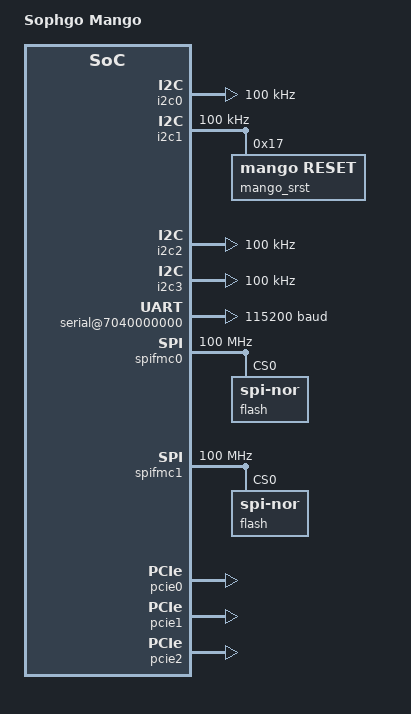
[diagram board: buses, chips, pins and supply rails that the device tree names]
/dts-v1/;

/ {
	model = "Sophgo Mango";
	compatible = "sophgo,mango";
	#address-cells = <2>;
	#size-cells = <2>;
	dma-noncoherent;

	info {
		file-name = "mango-sophgo-x4evb.dts";
	};

	cpus {
		#address-cells = <1>;
		#size-cells = <0>;
		timebase-frequency = <50000000>;

		cpu0: cpu@0 {
			compatible = "thead,c920", "riscv";
			device_type = "cpu";
			riscv,isa = "rv64imafdc_xtheadvector";
			riscv,isa-base = "rv64i";
			riscv,isa-extensions = "i", "m", "a", "f", "d", "c",
					"zicntr", "zicsr", "zifencei",
					"zihpm", "xtheadvector";
			reg = <0>;
			i-cache-block-size = <64>;
			i-cache-size = <65536>;
			i-cache-sets = <512>;
			d-cache-block-size = <64>;
			d-cache-size = <65536>;
			d-cache-sets = <512>;
			next-level-cache = <&l2_cache0>;
			mmu-type = "riscv,sv39";
			numa-node-id = <0>;

			cpu0_intc: interrupt-controller {
				#address-cells = <1>;
				compatible = "riscv,cpu-intc";
				interrupt-controller;
				#interrupt-cells = <1>;
			};
		};

		cpu1: cpu@1 {
			compatible = "thead,c920", "riscv";
			device_type = "cpu";
			riscv,isa = "rv64imafdc_xtheadvector";
			riscv,isa-base = "rv64i";
			riscv,isa-extensions = "i", "m", "a", "f", "d", "c",
					"zicntr", "zicsr", "zifencei",
					"zihpm", "xtheadvector";
			reg = <1>;
			i-cache-block-size = <64>;
			i-cache-size = <65536>;
			i-cache-sets = <512>;
			d-cache-block-size = <64>;
			d-cache-size = <65536>;
			d-cache-sets = <512>;
			next-level-cache = <&l2_cache0>;
			mmu-type = "riscv,sv39";
			numa-node-id = <0>;

			cpu1_intc: interrupt-controller {
				#address-cells = <1>;
				compatible = "riscv,cpu-intc";
				interrupt-controller;
				#interrupt-cells = <1>;
			};
		};

		cpu2: cpu@2 {
			compatible = "thead,c920", "riscv";
			device_type = "cpu";
			riscv,isa = "rv64imafdc_xtheadvector";
			riscv,isa-base = "rv64i";
			riscv,isa-extensions = "i", "m", "a", "f", "d", "c",
					"zicntr", "zicsr", "zifencei",
					"zihpm", "xtheadvector";
			reg = <2>;
			i-cache-size = <65536>;
			i-cache-sets = <512>;
			d-cache-block-size = <64>;
			d-cache-size = <65536>;
			d-cache-sets = <512>;
			next-level-cache = <&l2_cache0>;
			mmu-type = "riscv,sv39";
			numa-node-id = <0>;

			cpu2_intc: interrupt-controller {
				#address-cells = <1>;
				compatible = "riscv,cpu-intc";
				interrupt-controller;
				#interrupt-cells = <1>;
			};
		};

		cpu3: cpu@3 {
			compatible = "thead,c920", "riscv";
			device_type = "cpu";
			riscv,isa = "rv64imafdc_xtheadvector";
			riscv,isa-base = "rv64i";
			riscv,isa-extensions = "i", "m", "a", "f", "d", "c",
					"zicntr", "zicsr", "zifencei",
					"zihpm", "xtheadvector";
			reg = <3>;
			i-cache-size = <65536>;
			i-cache-sets = <512>;
			d-cache-block-size = <64>;
			d-cache-size = <65536>;
			d-cache-sets = <512>;
			next-level-cache = <&l2_cache0>;
			mmu-type = "riscv,sv39";
			numa-node-id = <0>;

			cpu3_intc: interrupt-controller {
				#address-cells = <1>;
				compatible = "riscv,cpu-intc";
				interrupt-controller;
				#interrupt-cells = <1>;
			};
		};

		cpu4: cpu@4 {
			compatible = "thead,c920", "riscv";
			device_type = "cpu";
			riscv,isa = "rv64imafdc_xtheadvector";
			riscv,isa-base = "rv64i";
			riscv,isa-extensions = "i", "m", "a", "f", "d", "c",
					"zicntr", "zicsr", "zifencei",
					"zihpm", "xtheadvector";
			reg = <4>;
			i-cache-size = <65536>;
			i-cache-sets = <512>;
			d-cache-block-size = <64>;
			d-cache-size = <65536>;
			d-cache-sets = <512>;
			next-level-cache = <&l2_cache1>;
			mmu-type = "riscv,sv39";
			numa-node-id = <0>;

			cpu4_intc: interrupt-controller {
				#address-cells = <1>;
				compatible = "riscv,cpu-intc";
				interrupt-controller;
				#interrupt-cells = <1>;
			};
		};

		cpu5: cpu@5 {
			compatible = "thead,c920", "riscv";
			device_type = "cpu";
			riscv,isa = "rv64imafdc_xtheadvector";
			riscv,isa-base = "rv64i";
			riscv,isa-extensions = "i", "m", "a", "f", "d", "c",
					"zicntr", "zicsr", "zifencei",
					"zihpm", "xtheadvector";
			reg = <5>;
			i-cache-size = <65536>;
			i-cache-sets = <512>;
			d-cache-block-size = <64>;
			d-cache-size = <65536>;
			d-cache-sets = <512>;
			next-level-cache = <&l2_cache1>;
			mmu-type = "riscv,sv39";
			numa-node-id = <0>;

			cpu5_intc: interrupt-controller {
				#address-cells = <1>;
				compatible = "riscv,cpu-intc";
				interrupt-controller;
				#interrupt-cells = <1>;
			};
		};

		cpu6: cpu@6 {
			compatible = "thead,c920", "riscv";
			device_type = "cpu";
			riscv,isa = "rv64imafdc_xtheadvector";
			riscv,isa-base = "rv64i";
			riscv,isa-extensions = "i", "m", "a", "f", "d", "c",
					"zicntr", "zicsr", "zifencei",
					"zihpm", "xtheadvector";
			reg = <6>;
			i-cache-size = <65536>;
			i-cache-sets = <512>;
			d-cache-block-size = <64>;
			d-cache-size = <65536>;
			d-cache-sets = <512>;
			next-level-cache = <&l2_cache1>;
			mmu-type = "riscv,sv39";
			numa-node-id = <0>;

			cpu6_intc: interrupt-controller {
				#address-cells = <1>;
				compatible = "riscv,cpu-intc";
				interrupt-controller;
				#interrupt-cells = <1>;
			};
		};

		cpu7: cpu@7 {
			compatible = "thead,c920", "riscv";
			device_type = "cpu";
			riscv,isa = "rv64imafdc_xtheadvector";
			riscv,isa-base = "rv64i";
			riscv,isa-extensions = "i", "m", "a", "f", "d", "c",
					"zicntr", "zicsr", "zifencei",
					"zihpm", "xtheadvector";
			reg = <7>;
			i-cache-size = <65536>;
			i-cache-sets = <512>;
			d-cache-block-size = <64>;
			d-cache-size = <65536>;
			d-cache-sets = <512>;
			next-level-cache = <&l2_cache1>;
			mmu-type = "riscv,sv39";
			numa-node-id = <0>;

			cpu7_intc: interrupt-controller {
				#address-cells = <1>;
				compatible = "riscv,cpu-intc";
				interrupt-controller;
				#interrupt-cells = <1>;
			};
		};

		cpu8: cpu@8 {
			compatible = "thead,c920", "riscv";
			device_type = "cpu";
			riscv,isa = "rv64imafdc_xtheadvector";
			riscv,isa-base = "rv64i";
			riscv,isa-extensions = "i", "m", "a", "f", "d", "c",
					"zicntr", "zicsr", "zifencei",
					"zihpm", "xtheadvector";
			reg = <8>;
			i-cache-size = <65536>;
			i-cache-sets = <512>;
			d-cache-block-size = <64>;
			d-cache-size = <65536>;
			d-cache-sets = <512>;
			next-level-cache = <&l2_cache4>;
			mmu-type = "riscv,sv39";
			numa-node-id = <1>;

			cpu8_intc: interrupt-controller {
				#address-cells = <1>;
				compatible = "riscv,cpu-intc";
				interrupt-controller;
				#interrupt-cells = <1>;
			};
		};

		cpu9: cpu@9 {
			compatible = "thead,c920", "riscv";
			device_type = "cpu";
			riscv,isa = "rv64imafdc_xtheadvector";
			riscv,isa-base = "rv64i";
			riscv,isa-extensions = "i", "m", "a", "f", "d", "c",
					"zicntr", "zicsr", "zifencei",
					"zihpm", "xtheadvector";
			reg = <9>;
			i-cache-size = <65536>;
			i-cache-sets = <512>;
			d-cache-block-size = <64>;
			d-cache-size = <65536>;
			d-cache-sets = <512>;
			next-level-cache = <&l2_cache4>;
			mmu-type = "riscv,sv39";
			numa-node-id = <1>;

			cpu9_intc: interrupt-controller {
				#address-cells = <1>;
				compatible = "riscv,cpu-intc";
				interrupt-controller;
				#interrupt-cells = <1>;
			};
		};

		cpu10: cpu@10 {
			compatible = "thead,c920", "riscv";
			device_type = "cpu";
			riscv,isa = "rv64imafdc_xtheadvector";
			riscv,isa-base = "rv64i";
			riscv,isa-extensions = "i", "m", "a", "f", "d", "c",
					"zicntr", "zicsr", "zifencei",
					"zihpm", "xtheadvector";
			reg = <10>;
			i-cache-size = <65536>;
			i-cache-sets = <512>;
			d-cache-block-size = <64>;
			d-cache-size = <65536>;
			d-cache-sets = <512>;
			next-level-cache = <&l2_cache4>;
			mmu-type = "riscv,sv39";
			numa-node-id = <1>;

			cpu10_intc: interrupt-controller {
				#address-cells = <1>;
				compatible = "riscv,cpu-intc";
				interrupt-controller;
				#interrupt-cells = <1>;
			};
		};

		cpu11: cpu@11 {
			compatible = "thead,c920", "riscv";
			device_type = "cpu";
			riscv,isa = "rv64imafdc_xtheadvector";
			riscv,isa-base = "rv64i";
			riscv,isa-extensions = "i", "m", "a", "f", "d", "c",
					"zicntr", "zicsr", "zifencei",
					"zihpm", "xtheadvector";
			reg = <11>;
			i-cache-size = <65536>;
			i-cache-sets = <512>;
			d-cache-block-size = <64>;
			d-cache-size = <65536>;
			d-cache-sets = <512>;
			next-level-cache = <&l2_cache4>;
			mmu-type = "riscv,sv39";
			numa-node-id = <1>;

			cpu11_intc: interrupt-controller {
				#address-cells = <1>;
				compatible = "riscv,cpu-intc";
				interrupt-controller;
				#interrupt-cells = <1>;
			};
		};

		cpu12: cpu@12 {
			compatible = "thead,c920", "riscv";
			device_type = "cpu";
			riscv,isa = "rv64imafdc_xtheadvector";
			riscv,isa-base = "rv64i";
			riscv,isa-extensions = "i", "m", "a", "f", "d", "c",
					"zicntr", "zicsr", "zifencei",
					"zihpm", "xtheadvector";
			reg = <12>;
			i-cache-size = <65536>;
			i-cache-sets = <512>;
			d-cache-block-size = <64>;
			d-cache-size = <65536>;
			d-cache-sets = <512>;
			next-level-cache = <&l2_cache5>;
			mmu-type = "riscv,sv39";
			numa-node-id = <1>;

			cpu12_intc: interrupt-controller {
				#address-cells = <1>;
				compatible = "riscv,cpu-intc";
				interrupt-controller;
				#interrupt-cells = <1>;
			};
		};

		cpu13: cpu@13 {
			compatible = "thead,c920", "riscv";
			device_type = "cpu";
			riscv,isa = "rv64imafdc_xtheadvector";
			riscv,isa-base = "rv64i";
			riscv,isa-extensions = "i", "m", "a", "f", "d", "c",
					"zicntr", "zicsr", "zifencei",
					"zihpm", "xtheadvector";
			reg = <13>;
			i-cache-size = <65536>;
			i-cache-sets = <512>;
			d-cache-block-size = <64>;
			d-cache-size = <65536>;
			d-cache-sets = <512>;
			next-level-cache = <&l2_cache5>;
			mmu-type = "riscv,sv39";
			numa-node-id = <1>;

			cpu13_intc: interrupt-controller {
				#address-cells = <1>;
				compatible = "riscv,cpu-intc";
				interrupt-controller;
				#interrupt-cells = <1>;
			};
		};

		cpu14: cpu@14 {
			compatible = "thead,c920", "riscv";
			device_type = "cpu";
			riscv,isa = "rv64imafdc_xtheadvector";
			riscv,isa-base = "rv64i";
			riscv,isa-extensions = "i", "m", "a", "f", "d", "c",
					"zicntr", "zicsr", "zifencei",
					"zihpm", "xtheadvector";
			reg = <14>;
			i-cache-size = <65536>;
			i-cache-sets = <512>;
			d-cache-block-size = <64>;
			d-cache-size = <65536>;
			d-cache-sets = <512>;
			next-level-cache = <&l2_cache5>;
			mmu-type = "riscv,sv39";
			numa-node-id = <1>;

			cpu14_intc: interrupt-controller {
				#address-cells = <1>;
				compatible = "riscv,cpu-intc";
				interrupt-controller;
				#interrupt-cells = <1>;
			};
		};

		cpu15: cpu@15 {
			compatible = "thead,c920", "riscv";
			device_type = "cpu";
			riscv,isa = "rv64imafdc_xtheadvector";
			riscv,isa-base = "rv64i";
			riscv,isa-extensions = "i", "m", "a", "f", "d", "c",
					"zicntr", "zicsr", "zifencei",
					"zihpm", "xtheadvector";
			reg = <15>;
			i-cache-size = <65536>;
			i-cache-sets = <512>;
			d-cache-block-size = <64>;
			d-cache-size = <65536>;
			d-cache-sets = <512>;
			next-level-cache = <&l2_cache5>;
			mmu-type = "riscv,sv39";
			numa-node-id = <1>;

			cpu15_intc: interrupt-controller {
				#address-cells = <1>;
				compatible = "riscv,cpu-intc";
				interrupt-controller;
				#interrupt-cells = <1>;
			};
		};

		cpu16: cpu@16 {
			compatible = "thead,c920", "riscv";
			device_type = "cpu";
			riscv,isa = "rv64imafdc_xtheadvector";
			riscv,isa-base = "rv64i";
			riscv,isa-extensions = "i", "m", "a", "f", "d", "c",
					"zicntr", "zicsr", "zifencei",
					"zihpm", "xtheadvector";
			reg = <16>;
			i-cache-size = <65536>;
			i-cache-sets = <512>;
			d-cache-block-size = <64>;
			d-cache-size = <65536>;
			d-cache-sets = <512>;
			next-level-cache = <&l2_cache2>;
			mmu-type = "riscv,sv39";
			numa-node-id = <0>;

			cpu16_intc: interrupt-controller {
				#address-cells = <1>;
				compatible = "riscv,cpu-intc";
				interrupt-controller;
				#interrupt-cells = <1>;
			};
		};

		cpu17: cpu@17 {
			compatible = "thead,c920", "riscv";
			device_type = "cpu";
			riscv,isa = "rv64imafdc_xtheadvector";
			riscv,isa-base = "rv64i";
			riscv,isa-extensions = "i", "m", "a", "f", "d", "c",
					"zicntr", "zicsr", "zifencei",
					"zihpm", "xtheadvector";
			reg = <17>;
			i-cache-size = <65536>;
			i-cache-sets = <512>;
			d-cache-block-size = <64>;
			d-cache-size = <65536>;
			d-cache-sets = <512>;
			next-level-cache = <&l2_cache2>;
			mmu-type = "riscv,sv39";
			numa-node-id = <0>;

			cpu17_intc: interrupt-controller {
				#address-cells = <1>;
				compatible = "riscv,cpu-intc";
				interrupt-controller;
				#interrupt-cells = <1>;
			};
		};

		cpu18: cpu@18 {
			compatible = "thead,c920", "riscv";
			device_type = "cpu";
			riscv,isa = "rv64imafdc_xtheadvector";
			riscv,isa-base = "rv64i";
			riscv,isa-extensions = "i", "m", "a", "f", "d", "c",
					"zicntr", "zicsr", "zifencei",
					"zihpm", "xtheadvector";
			reg = <18>;
			i-cache-size = <65536>;
			i-cache-sets = <512>;
			d-cache-block-size = <64>;
			d-cache-size = <65536>;
			d-cache-sets = <512>;
			next-level-cache = <&l2_cache2>;
			mmu-type = "riscv,sv39";
			numa-node-id = <0>;

			cpu18_intc: interrupt-controller {
				#address-cells = <1>;
				compatible = "riscv,cpu-intc";
				interrupt-controller;
				#interrupt-cells = <1>;
			};
		};

		cpu19: cpu@19 {
			compatible = "thead,c920", "riscv";
			device_type = "cpu";
			riscv,isa = "rv64imafdc_xtheadvector";
			riscv,isa-base = "rv64i";
			riscv,isa-extensions = "i", "m", "a", "f", "d", "c",
					"zicntr", "zicsr", "zifencei",
					"zihpm", "xtheadvector";
			reg = <19>;
			i-cache-size = <65536>;
			i-cache-sets = <512>;
			d-cache-block-size = <64>;
			d-cache-size = <65536>;
			d-cache-sets = <512>;
			next-level-cache = <&l2_cache2>;
			mmu-type = "riscv,sv39";
			numa-node-id = <0>;

			cpu19_intc: interrupt-controller {
				#address-cells = <1>;
				compatible = "riscv,cpu-intc";
				interrupt-controller;
				#interrupt-cells = <1>;
			};
		};

		cpu20: cpu@20 {
			compatible = "thead,c920", "riscv";
			device_type = "cpu";
			riscv,isa = "rv64imafdc_xtheadvector";
			riscv,isa-base = "rv64i";
			riscv,isa-extensions = "i", "m", "a", "f", "d", "c",
					"zicntr", "zicsr", "zifencei",
					"zihpm", "xtheadvector";
			reg = <20>;
			i-cache-size = <65536>;
			i-cache-sets = <512>;
			d-cache-block-size = <64>;
			d-cache-size = <65536>;
			d-cache-sets = <512>;
			next-level-cache = <&l2_cache3>;
			mmu-type = "riscv,sv39";
			numa-node-id = <0>;

			cpu20_intc: interrupt-controller {
				#address-cells = <1>;
				compatible = "riscv,cpu-intc";
				interrupt-controller;
				#interrupt-cells = <1>;
			};
		};

		cpu21: cpu@21 {
			compatible = "thead,c920", "riscv";
			device_type = "cpu";
			riscv,isa = "rv64imafdc_xtheadvector";
			riscv,isa-base = "rv64i";
			riscv,isa-extensions = "i", "m", "a", "f", "d", "c",
					"zicntr", "zicsr", "zifencei",
					"zihpm", "xtheadvector";
			reg = <21>;
			i-cache-size = <65536>;
			i-cache-sets = <512>;
			d-cache-block-size = <64>;
			d-cache-size = <65536>;
			d-cache-sets = <512>;
			next-level-cache = <&l2_cache3>;
			mmu-type = "riscv,sv39";
			numa-node-id = <0>;

			cpu21_intc: interrupt-controller {
				#address-cells = <1>;
				compatible = "riscv,cpu-intc";
				interrupt-controller;
				#interrupt-cells = <1>;
			};
		};

		cpu22: cpu@22 {
			compatible = "thead,c920", "riscv";
			device_type = "cpu";
			riscv,isa = "rv64imafdc_xtheadvector";
			riscv,isa-base = "rv64i";
			riscv,isa-extensions = "i", "m", "a", "f", "d", "c",
					"zicntr", "zicsr", "zifencei",
					"zihpm", "xtheadvector";
			reg = <22>;
			i-cache-size = <65536>;
			i-cache-sets = <512>;
			d-cache-block-size = <64>;
			d-cache-size = <65536>;
			d-cache-sets = <512>;
			next-level-cache = <&l2_cache3>;
			mmu-type = "riscv,sv39";
			numa-node-id = <0>;

			cpu22_intc: interrupt-controller {
				#address-cells = <1>;
				compatible = "riscv,cpu-intc";
				interrupt-controller;
				#interrupt-cells = <1>;
			};
		};

		cpu23: cpu@23 {
			compatible = "thead,c920", "riscv";
			device_type = "cpu";
			riscv,isa = "rv64imafdc_xtheadvector";
			riscv,isa-base = "rv64i";
			riscv,isa-extensions = "i", "m", "a", "f", "d", "c",
					"zicntr", "zicsr", "zifencei",
					"zihpm", "xtheadvector";
			reg = <23>;
			i-cache-block-size = <64>;
			i-cache-size = <65536>;
			i-cache-sets = <512>;
			d-cache-block-size = <64>;
			d-cache-size = <65536>;
			d-cache-sets = <512>;
			next-level-cache = <&l2_cache3>;
			mmu-type = "riscv,sv39";
			numa-node-id = <0>;

			cpu23_intc: interrupt-controller {
				#address-cells = <1>;
				compatible = "riscv,cpu-intc";
				interrupt-controller;
				#interrupt-cells = <1>;
			};
		};

		cpu24: cpu@24 {
			compatible = "thead,c920", "riscv";
			device_type = "cpu";
			riscv,isa = "rv64imafdc_xtheadvector";
			riscv,isa-base = "rv64i";
			riscv,isa-extensions = "i", "m", "a", "f", "d", "c",
					"zicntr", "zicsr", "zifencei",
					"zihpm", "xtheadvector";
			reg = <24>;
			i-cache-size = <65536>;
			i-cache-sets = <512>;
			d-cache-block-size = <64>;
			d-cache-size = <65536>;
			d-cache-sets = <512>;
			next-level-cache = <&l2_cache6>;
			mmu-type = "riscv,sv39";
			numa-node-id = <1>;

			cpu24_intc: interrupt-controller {
				#address-cells = <1>;
				compatible = "riscv,cpu-intc";
				interrupt-controller;
				#interrupt-cells = <1>;
			};
		};

		cpu25: cpu@25 {
			compatible = "thead,c920", "riscv";
			device_type = "cpu";
			riscv,isa = "rv64imafdc_xtheadvector";
			riscv,isa-base = "rv64i";
			riscv,isa-extensions = "i", "m", "a", "f", "d", "c",
					"zicntr", "zicsr", "zifencei",
					"zihpm", "xtheadvector";
			reg = <25>;
			i-cache-size = <65536>;
			i-cache-sets = <512>;
			d-cache-block-size = <64>;
			d-cache-size = <65536>;
			d-cache-sets = <512>;
			next-level-cache = <&l2_cache6>;
			mmu-type = "riscv,sv39";
			numa-node-id = <1>;

			cpu25_intc: interrupt-controller {
				#address-cells = <1>;
				compatible = "riscv,cpu-intc";
				interrupt-controller;
				#interrupt-cells = <1>;
			};
		};

		cpu26: cpu@26 {
			compatible = "thead,c920", "riscv";
			device_type = "cpu";
			riscv,isa = "rv64imafdc_xtheadvector";
			riscv,isa-base = "rv64i";
			riscv,isa-extensions = "i", "m", "a", "f", "d", "c",
					"zicntr", "zicsr", "zifencei",
					"zihpm", "xtheadvector";
			reg = <26>;
			i-cache-size = <65536>;
			i-cache-sets = <512>;
			d-cache-block-size = <64>;
			d-cache-size = <65536>;
			d-cache-sets = <512>;
			next-level-cache = <&l2_cache6>;
			mmu-type = "riscv,sv39";
			numa-node-id = <1>;

			cpu26_intc: interrupt-controller {
				#address-cells = <1>;
				compatible = "riscv,cpu-intc";
				interrupt-controller;
				#interrupt-cells = <1>;
			};
		};

		cpu27: cpu@27 {
			compatible = "thead,c920", "riscv";
			device_type = "cpu";
			riscv,isa = "rv64imafdc_xtheadvector";
			riscv,isa-base = "rv64i";
			riscv,isa-extensions = "i", "m", "a", "f", "d", "c",
					"zicntr", "zicsr", "zifencei",
					"zihpm", "xtheadvector";
			reg = <27>;
			i-cache-size = <65536>;
			i-cache-sets = <512>;
			d-cache-block-size = <64>;
			d-cache-size = <65536>;
			d-cache-sets = <512>;
			next-level-cache = <&l2_cache6>;
			mmu-type = "riscv,sv39";
			numa-node-id = <1>;

			cpu27_intc: interrupt-controller {
				#address-cells = <1>;
				compatible = "riscv,cpu-intc";
				interrupt-controller;
				#interrupt-cells = <1>;
			};
		};

		cpu28: cpu@28 {
			compatible = "thead,c920", "riscv";
			device_type = "cpu";
			riscv,isa = "rv64imafdc_xtheadvector";
			riscv,isa-base = "rv64i";
			riscv,isa-extensions = "i", "m", "a", "f", "d", "c",
					"zicntr", "zicsr", "zifencei",
					"zihpm", "xtheadvector";
			reg = <28>;
			i-cache-size = <65536>;
			i-cache-sets = <512>;
			d-cache-block-size = <64>;
			d-cache-size = <65536>;
			d-cache-sets = <512>;
			next-level-cache = <&l2_cache7>;
			mmu-type = "riscv,sv39";
			numa-node-id = <1>;

			cpu28_intc: interrupt-controller {
				#address-cells = <1>;
				compatible = "riscv,cpu-intc";
				interrupt-controller;
				#interrupt-cells = <1>;
			};
		};

		cpu29: cpu@29 {
			compatible = "thead,c920", "riscv";
			device_type = "cpu";
			riscv,isa = "rv64imafdc_xtheadvector";
			riscv,isa-base = "rv64i";
			riscv,isa-extensions = "i", "m", "a", "f", "d", "c",
					"zicntr", "zicsr", "zifencei",
					"zihpm", "xtheadvector";
			reg = <29>;
			i-cache-size = <65536>;
			i-cache-sets = <512>;
			d-cache-block-size = <64>;
			d-cache-size = <65536>;
			d-cache-sets = <512>;
			next-level-cache = <&l2_cache7>;
			mmu-type = "riscv,sv39";
			numa-node-id = <1>;

			cpu29_intc: interrupt-controller {
				#address-cells = <1>;
				compatible = "riscv,cpu-intc";
				interrupt-controller;
				#interrupt-cells = <1>;
			};
		};

		cpu30: cpu@30 {
			compatible = "thead,c920", "riscv";
			device_type = "cpu";
			riscv,isa = "rv64imafdc_xtheadvector";
			riscv,isa-base = "rv64i";
			riscv,isa-extensions = "i", "m", "a", "f", "d", "c",
					"zicntr", "zicsr", "zifencei",
					"zihpm", "xtheadvector";
			reg = <30>;
			i-cache-size = <65536>;
			i-cache-sets = <512>;
			d-cache-block-size = <64>;
			d-cache-size = <65536>;
			d-cache-sets = <512>;
			next-level-cache = <&l2_cache7>;
			mmu-type = "riscv,sv39";
			numa-node-id = <1>;

			cpu30_intc: interrupt-controller {
				#address-cells = <1>;
				compatible = "riscv,cpu-intc";
				interrupt-controller;
				#interrupt-cells = <1>;
			};
		};

		cpu31: cpu@31 {
			compatible = "thead,c920", "riscv";
			device_type = "cpu";
			riscv,isa = "rv64imafdc_xtheadvector";
			riscv,isa-base = "rv64i";
			riscv,isa-extensions = "i", "m", "a", "f", "d", "c",
					"zicntr", "zicsr", "zifencei",
					"zihpm", "xtheadvector";
			reg = <31>;
			i-cache-block-size = <64>;
			i-cache-size = <65536>;
			i-cache-sets = <512>;
			d-cache-block-size = <64>;
			d-cache-size = <65536>;
			d-cache-sets = <512>;
			next-level-cache = <&l2_cache7>;
			mmu-type = "riscv,sv39";
			numa-node-id = <1>;

			cpu31_intc: interrupt-controller {
				#address-cells = <1>;
				compatible = "riscv,cpu-intc";
				interrupt-controller;
				#interrupt-cells = <1>;
			};
		};

		cpu32: cpu@32 {
			compatible = "thead,c920", "riscv";
			device_type = "cpu";
			riscv,isa = "rv64imafdc_xtheadvector";
			riscv,isa-base = "rv64i";
			riscv,isa-extensions = "i", "m", "a", "f", "d", "c",
					"zicntr", "zicsr", "zifencei",
					"zihpm", "xtheadvector";
			reg = <32>;
			i-cache-size = <65536>;
			i-cache-sets = <512>;
			d-cache-block-size = <64>;
			d-cache-size = <65536>;
			d-cache-sets = <512>;
			next-level-cache = <&l2_cache8>;
			mmu-type = "riscv,sv39";
			numa-node-id = <2>;

			cpu32_intc: interrupt-controller {
				#address-cells = <1>;
				compatible = "riscv,cpu-intc";
				interrupt-controller;
				#interrupt-cells = <1>;
			};
		};

		cpu33: cpu@33 {
			compatible = "thead,c920", "riscv";
			device_type = "cpu";
			riscv,isa = "rv64imafdc_xtheadvector";
			riscv,isa-base = "rv64i";
			riscv,isa-extensions = "i", "m", "a", "f", "d", "c",
					"zicntr", "zicsr", "zifencei",
					"zihpm", "xtheadvector";
			reg = <33>;
			i-cache-size = <65536>;
			i-cache-sets = <512>;
			d-cache-block-size = <64>;
			d-cache-size = <65536>;
			d-cache-sets = <512>;
			next-level-cache = <&l2_cache8>;
			mmu-type = "riscv,sv39";
			numa-node-id = <2>;

			cpu33_intc: interrupt-controller {
				#address-cells = <1>;
				compatible = "riscv,cpu-intc";
				interrupt-controller;
				#interrupt-cells = <1>;
			};
		};

		cpu34: cpu@34 {
			compatible = "thead,c920", "riscv";
			device_type = "cpu";
			riscv,isa = "rv64imafdc_xtheadvector";
			riscv,isa-base = "rv64i";
			riscv,isa-extensions = "i", "m", "a", "f", "d", "c",
					"zicntr", "zicsr", "zifencei",
					"zihpm", "xtheadvector";
			reg = <34>;
			i-cache-size = <65536>;
			i-cache-sets = <512>;
			d-cache-block-size = <64>;
			d-cache-size = <65536>;
			d-cache-sets = <512>;
			next-level-cache = <&l2_cache8>;
			mmu-type = "riscv,sv39";
			numa-node-id = <2>;

			cpu34_intc: interrupt-controller {
				#address-cells = <1>;
				compatible = "riscv,cpu-intc";
				interrupt-controller;
				#interrupt-cells = <1>;
			};
		};

		cpu35: cpu@35 {
			compatible = "thead,c920", "riscv";
			device_type = "cpu";
			riscv,isa = "rv64imafdc_xtheadvector";
			riscv,isa-base = "rv64i";
			riscv,isa-extensions = "i", "m", "a", "f", "d", "c",
					"zicntr", "zicsr", "zifencei",
					"zihpm", "xtheadvector";
			reg = <35>;
			i-cache-size = <65536>;
			i-cache-sets = <512>;
			d-cache-block-size = <64>;
			d-cache-size = <65536>;
			d-cache-sets = <512>;
			next-level-cache = <&l2_cache8>;
			mmu-type = "riscv,sv39";
			numa-node-id = <2>;

			cpu35_intc: interrupt-controller {
				#address-cells = <1>;
				compatible = "riscv,cpu-intc";
				interrupt-controller;
				#interrupt-cells = <1>;
			};
		};

		cpu36: cpu@36 {
			compatible = "thead,c920", "riscv";
			device_type = "cpu";
			riscv,isa = "rv64imafdc_xtheadvector";
			riscv,isa-base = "rv64i";
			riscv,isa-extensions = "i", "m", "a", "f", "d", "c",
					"zicntr", "zicsr", "zifencei",
					"zihpm", "xtheadvector";
			reg = <36>;
			i-cache-size = <65536>;
			i-cache-sets = <512>;
			d-cache-block-size = <64>;
			d-cache-size = <65536>;
			d-cache-sets = <512>;
			next-level-cache = <&l2_cache9>;
			mmu-type = "riscv,sv39";
			numa-node-id = <2>;

			cpu36_intc: interrupt-controller {
				#address-cells = <1>;
				compatible = "riscv,cpu-intc";
				interrupt-controller;
				#interrupt-cells = <1>;
			};
		};

		cpu37: cpu@37 {
			compatible = "thead,c920", "riscv";
			device_type = "cpu";
			riscv,isa = "rv64imafdc_xtheadvector";
			riscv,isa-base = "rv64i";
			riscv,isa-extensions = "i", "m", "a", "f", "d", "c",
					"zicntr", "zicsr", "zifencei",
					"zihpm", "xtheadvector";
			reg = <37>;
			i-cache-size = <65536>;
			i-cache-sets = <512>;
			d-cache-block-size = <64>;
			d-cache-size = <65536>;
			d-cache-sets = <512>;
			next-level-cache = <&l2_cache9>;
			mmu-type = "riscv,sv39";
			numa-node-id = <2>;

			cpu37_intc: interrupt-controller {
				#address-cells = <1>;
				compatible = "riscv,cpu-intc";
				interrupt-controller;
				#interrupt-cells = <1>;
			};
		};

		cpu38: cpu@38 {
			compatible = "thead,c920", "riscv";
			device_type = "cpu";
			riscv,isa = "rv64imafdc_xtheadvector";
			riscv,isa-base = "rv64i";
			riscv,isa-extensions = "i", "m", "a", "f", "d", "c",
					"zicntr", "zicsr", "zifencei",
					"zihpm", "xtheadvector";
			reg = <38>;
			i-cache-size = <65536>;
			i-cache-sets = <512>;
			d-cache-block-size = <64>;
			d-cache-size = <65536>;
			d-cache-sets = <512>;
			next-level-cache = <&l2_cache9>;
			mmu-type = "riscv,sv39";
			numa-node-id = <2>;

			cpu38_intc: interrupt-controller {
				#address-cells = <1>;
				compatible = "riscv,cpu-intc";
				interrupt-controller;
				#interrupt-cells = <1>;
			};
		};

		cpu39: cpu@39 {
			compatible = "thead,c920", "riscv";
			device_type = "cpu";
			riscv,isa = "rv64imafdc_xtheadvector";
			riscv,isa-base = "rv64i";
			riscv,isa-extensions = "i", "m", "a", "f", "d", "c",
					"zicntr", "zicsr", "zifencei",
					"zihpm", "xtheadvector";
			reg = <39>;
			i-cache-size = <65536>;
			i-cache-sets = <512>;
			d-cache-block-size = <64>;
			d-cache-size = <65536>;
			d-cache-sets = <512>;
			next-level-cache = <&l2_cache9>;
			mmu-type = "riscv,sv39";
			numa-node-id = <2>;

			cpu39_intc: interrupt-controller {
				#address-cells = <1>;
				compatible = "riscv,cpu-intc";
				interrupt-controller;
				#interrupt-cells = <1>;
			};
		};

		cpu40: cpu@40 {
			compatible = "thead,c920", "riscv";
			device_type = "cpu";
			riscv,isa = "rv64imafdc_xtheadvector";
			riscv,isa-base = "rv64i";
			riscv,isa-extensions = "i", "m", "a", "f", "d", "c",
					"zicntr", "zicsr", "zifencei",
					"zihpm", "xtheadvector";
			reg = <40>;
			i-cache-size = <65536>;
			i-cache-sets = <512>;
			d-cache-block-size = <64>;
			d-cache-size = <65536>;
			d-cache-sets = <512>;
			next-level-cache = <&l2_cache12>;
			mmu-type = "riscv,sv39";
			numa-node-id = <3>;

			cpu40_intc: interrupt-controller {
				#address-cells = <1>;
				compatible = "riscv,cpu-intc";
				interrupt-controller;
				#interrupt-cells = <1>;
			};
		};

		cpu41: cpu@41 {
			compatible = "thead,c920", "riscv";
			device_type = "cpu";
			riscv,isa = "rv64imafdc_xtheadvector";
			riscv,isa-base = "rv64i";
			riscv,isa-extensions = "i", "m", "a", "f", "d", "c",
					"zicntr", "zicsr", "zifencei",
					"zihpm", "xtheadvector";
			reg = <41>;
			i-cache-size = <65536>;
			i-cache-sets = <512>;
			d-cache-block-size = <64>;
			d-cache-size = <65536>;
			d-cache-sets = <512>;
			next-level-cache = <&l2_cache12>;
			mmu-type = "riscv,sv39";
			numa-node-id = <3>;

			cpu41_intc: interrupt-controller {
				#address-cells = <1>;
				compatible = "riscv,cpu-intc";
				interrupt-controller;
				#interrupt-cells = <1>;
			};
		};

		cpu42: cpu@42 {
			compatible = "thead,c920", "riscv";
			device_type = "cpu";
			riscv,isa = "rv64imafdc_xtheadvector";
			riscv,isa-base = "rv64i";
			riscv,isa-extensions = "i", "m", "a", "f", "d", "c",
					"zicntr", "zicsr", "zifencei",
					"zihpm", "xtheadvector";
			reg = <42>;
			i-cache-size = <65536>;
			i-cache-sets = <512>;
			d-cache-block-size = <64>;
			d-cache-size = <65536>;
			d-cache-sets = <512>;
			next-level-cache = <&l2_cache12>;
			mmu-type = "riscv,sv39";
			numa-node-id = <3>;

			cpu42_intc: interrupt-controller {
				#address-cells = <1>;
				compatible = "riscv,cpu-intc";
				interrupt-controller;
				#interrupt-cells = <1>;
			};
		};

		cpu43: cpu@43 {
			compatible = "thead,c920", "riscv";
			device_type = "cpu";
			riscv,isa = "rv64imafdc_xtheadvector";
			riscv,isa-base = "rv64i";
			riscv,isa-extensions = "i", "m", "a", "f", "d", "c",
					"zicntr", "zicsr", "zifencei",
					"zihpm", "xtheadvector";
			reg = <43>;
			i-cache-size = <65536>;
			i-cache-sets = <512>;
			d-cache-block-size = <64>;
			d-cache-size = <65536>;
			d-cache-sets = <512>;
			next-level-cache = <&l2_cache12>;
			mmu-type = "riscv,sv39";
			numa-node-id = <3>;

			cpu43_intc: interrupt-controller {
				#address-cells = <1>;
				compatible = "riscv,cpu-intc";
				interrupt-controller;
				#interrupt-cells = <1>;
			};
		};

		cpu44: cpu@44 {
			compatible = "thead,c920", "riscv";
			device_type = "cpu";
			riscv,isa = "rv64imafdc_xtheadvector";
			riscv,isa-base = "rv64i";
			riscv,isa-extensions = "i", "m", "a", "f", "d", "c",
					"zicntr", "zicsr", "zifencei",
					"zihpm", "xtheadvector";
			reg = <44>;
			i-cache-size = <65536>;
			i-cache-sets = <512>;
			d-cache-block-size = <64>;
			d-cache-size = <65536>;
			d-cache-sets = <512>;
			next-level-cache = <&l2_cache13>;
			mmu-type = "riscv,sv39";
			numa-node-id = <3>;

			cpu44_intc: interrupt-controller {
				#address-cells = <1>;
				compatible = "riscv,cpu-intc";
				interrupt-controller;
				#interrupt-cells = <1>;
			};
		};

		cpu45: cpu@45 {
			compatible = "thead,c920", "riscv";
			device_type = "cpu";
			riscv,isa = "rv64imafdc_xtheadvector";
			riscv,isa-base = "rv64i";
			riscv,isa-extensions = "i", "m", "a", "f", "d", "c",
					"zicntr", "zicsr", "zifencei",
					"zihpm", "xtheadvector";
			reg = <45>;
			i-cache-size = <65536>;
			i-cache-sets = <512>;
			d-cache-block-size = <64>;
			d-cache-size = <65536>;
			d-cache-sets = <512>;
			next-level-cache = <&l2_cache13>;
			mmu-type = "riscv,sv39";
			numa-node-id = <3>;

			cpu45_intc: interrupt-controller {
				#address-cells = <1>;
				compatible = "riscv,cpu-intc";
				interrupt-controller;
				#interrupt-cells = <1>;
			};
		};

		cpu46: cpu@46 {
			compatible = "thead,c920", "riscv";
			device_type = "cpu";
			riscv,isa = "rv64imafdc_xtheadvector";
			riscv,isa-base = "rv64i";
			riscv,isa-extensions = "i", "m", "a", "f", "d", "c",
					"zicntr", "zicsr", "zifencei",
					"zihpm", "xtheadvector";
			reg = <46>;
			i-cache-size = <65536>;
			i-cache-sets = <512>;
			d-cache-block-size = <64>;
			d-cache-size = <65536>;
			d-cache-sets = <512>;
			next-level-cache = <&l2_cache13>;
			mmu-type = "riscv,sv39";
			numa-node-id = <3>;

			cpu46_intc: interrupt-controller {
				#address-cells = <1>;
				compatible = "riscv,cpu-intc";
				interrupt-controller;
				#interrupt-cells = <1>;
			};
		};

		cpu47: cpu@47 {
			compatible = "thead,c920", "riscv";
			device_type = "cpu";
			riscv,isa = "rv64imafdc_xtheadvector";
			riscv,isa-base = "rv64i";
			riscv,isa-extensions = "i", "m", "a", "f", "d", "c",
					"zicntr", "zicsr", "zifencei",
					"zihpm", "xtheadvector";
			reg = <47>;
			i-cache-size = <65536>;
			i-cache-sets = <512>;
			d-cache-block-size = <64>;
			d-cache-size = <65536>;
			d-cache-sets = <512>;
			next-level-cache = <&l2_cache13>;
			mmu-type = "riscv,sv39";
			numa-node-id = <3>;

			cpu47_intc: interrupt-controller {
				#address-cells = <1>;
				compatible = "riscv,cpu-intc";
				interrupt-controller;
				#interrupt-cells = <1>;
			};
		};

		cpu48: cpu@48 {
			compatible = "thead,c920", "riscv";
			device_type = "cpu";
			riscv,isa = "rv64imafdc_xtheadvector";
			riscv,isa-base = "rv64i";
			riscv,isa-extensions = "i", "m", "a", "f", "d", "c",
					"zicntr", "zicsr", "zifencei",
					"zihpm", "xtheadvector";
			reg = <48>;
			i-cache-size = <65536>;
			i-cache-sets = <512>;
			d-cache-block-size = <64>;
			d-cache-size = <65536>;
			d-cache-sets = <512>;
			next-level-cache = <&l2_cache10>;
			mmu-type = "riscv,sv39";
			numa-node-id = <2>;

			cpu48_intc: interrupt-controller {
				#address-cells = <1>;
				compatible = "riscv,cpu-intc";
				interrupt-controller;
				#interrupt-cells = <1>;
			};
		};

		cpu49: cpu@49 {
			compatible = "thead,c920", "riscv";
			device_type = "cpu";
			riscv,isa = "rv64imafdc_xtheadvector";
			riscv,isa-base = "rv64i";
			riscv,isa-extensions = "i", "m", "a", "f", "d", "c",
					"zicntr", "zicsr", "zifencei",
					"zihpm", "xtheadvector";
			reg = <49>;
			i-cache-size = <65536>;
			i-cache-sets = <512>;
			d-cache-block-size = <64>;
			d-cache-size = <65536>;
			d-cache-sets = <512>;
			next-level-cache = <&l2_cache10>;
			mmu-type = "riscv,sv39";
			numa-node-id = <2>;

			cpu49_intc: interrupt-controller {
				#address-cells = <1>;
				compatible = "riscv,cpu-intc";
				interrupt-controller;
				#interrupt-cells = <1>;
			};
		};

		cpu50: cpu@50 {
			compatible = "thead,c920", "riscv";
			device_type = "cpu";
			riscv,isa = "rv64imafdc_xtheadvector";
			riscv,isa-base = "rv64i";
			riscv,isa-extensions = "i", "m", "a", "f", "d", "c",
					"zicntr", "zicsr", "zifencei",
					"zihpm", "xtheadvector";
			reg = <50>;
			i-cache-size = <65536>;
			i-cache-sets = <512>;
			d-cache-block-size = <64>;
			d-cache-size = <65536>;
			d-cache-sets = <512>;
			next-level-cache = <&l2_cache10>;
			mmu-type = "riscv,sv39";
			numa-node-id = <2>;

			cpu50_intc: interrupt-controller {
				#address-cells = <1>;
				compatible = "riscv,cpu-intc";
				interrupt-controller;
				#interrupt-cells = <1>;
			};
		};

		cpu51: cpu@51 {
			compatible = "thead,c920", "riscv";
			device_type = "cpu";
			riscv,isa = "rv64imafdc_xtheadvector";
			riscv,isa-base = "rv64i";
			riscv,isa-extensions = "i", "m", "a", "f", "d", "c",
					"zicntr", "zicsr", "zifencei",
					"zihpm", "xtheadvector";
			reg = <51>;
			i-cache-size = <65536>;
			i-cache-sets = <512>;
			d-cache-block-size = <64>;
			d-cache-size = <65536>;
			d-cache-sets = <512>;
			next-level-cache = <&l2_cache10>;
			mmu-type = "riscv,sv39";
			numa-node-id = <2>;

			cpu51_intc: interrupt-controller {
				#address-cells = <1>;
				compatible = "riscv,cpu-intc";
				interrupt-controller;
				#interrupt-cells = <1>;
			};
		};

		cpu52: cpu@52 {
			compatible = "thead,c920", "riscv";
			device_type = "cpu";
			riscv,isa = "rv64imafdc_xtheadvector";
			riscv,isa-base = "rv64i";
			riscv,isa-extensions = "i", "m", "a", "f", "d", "c",
					"zicntr", "zicsr", "zifencei",
					"zihpm", "xtheadvector";
			reg = <52>;
			i-cache-size = <65536>;
			i-cache-sets = <512>;
			d-cache-block-size = <64>;
			d-cache-size = <65536>;
			d-cache-sets = <512>;
			next-level-cache = <&l2_cache11>;
			mmu-type = "riscv,sv39";
			numa-node-id = <2>;

			cpu52_intc: interrupt-controller {
				#address-cells = <1>;
				compatible = "riscv,cpu-intc";
				interrupt-controller;
				#interrupt-cells = <1>;
			};
		};

		cpu53: cpu@53 {
			compatible = "thead,c920", "riscv";
			device_type = "cpu";
			riscv,isa = "rv64imafdc_xtheadvector";
			riscv,isa-base = "rv64i";
			riscv,isa-extensions = "i", "m", "a", "f", "d", "c",
					"zicntr", "zicsr", "zifencei",
					"zihpm", "xtheadvector";
			reg = <53>;
			i-cache-size = <65536>;
			i-cache-sets = <512>;
			d-cache-block-size = <64>;
			d-cache-size = <65536>;
			d-cache-sets = <512>;
			next-level-cache = <&l2_cache11>;
			mmu-type = "riscv,sv39";
			numa-node-id = <2>;

			cpu53_intc: interrupt-controller {
				#address-cells = <1>;
				compatible = "riscv,cpu-intc";
				interrupt-controller;
				#interrupt-cells = <1>;
			};
		};

		cpu54: cpu@54 {
			compatible = "thead,c920", "riscv";
			device_type = "cpu";
			riscv,isa = "rv64imafdc_xtheadvector";
			riscv,isa-base = "rv64i";
			riscv,isa-extensions = "i", "m", "a", "f", "d", "c",
					"zicntr", "zicsr", "zifencei",
					"zihpm", "xtheadvector";
			reg = <54>;
			i-cache-size = <65536>;
			i-cache-sets = <512>;
			d-cache-block-size = <64>;
			d-cache-size = <65536>;
			d-cache-sets = <512>;
			next-level-cache = <&l2_cache11>;
			mmu-type = "riscv,sv39";
			numa-node-id = <2>;

			cpu54_intc: interrupt-controller {
				#address-cells = <1>;
				compatible = "riscv,cpu-intc";
				interrupt-controller;
				#interrupt-cells = <1>;
			};
		};

		cpu55: cpu@55 {
			compatible = "thead,c920", "riscv";
			device_type = "cpu";
			riscv,isa = "rv64imafdc_xtheadvector";
			riscv,isa-base = "rv64i";
			riscv,isa-extensions = "i", "m", "a", "f", "d", "c",
					"zicntr", "zicsr", "zifencei",
					"zihpm", "xtheadvector";
			reg = <55>;
			i-cache-block-size = <64>;
			i-cache-size = <65536>;
			i-cache-sets = <512>;
			d-cache-block-size = <64>;
			d-cache-size = <65536>;
			d-cache-sets = <512>;
			next-level-cache = <&l2_cache11>;
			mmu-type = "riscv,sv39";
			numa-node-id = <2>;

			cpu55_intc: interrupt-controller {
				#address-cells = <1>;
				compatible = "riscv,cpu-intc";
				interrupt-controller;
				#interrupt-cells = <1>;
			};
		};

		cpu56: cpu@56 {
			compatible = "thead,c920", "riscv";
			device_type = "cpu";
			riscv,isa = "rv64imafdc_xtheadvector";
			riscv,isa-base = "rv64i";
			riscv,isa-extensions = "i", "m", "a", "f", "d", "c",
					"zicntr", "zicsr", "zifencei",
					"zihpm", "xtheadvector";
			reg = <56>;
			i-cache-size = <65536>;
			i-cache-sets = <512>;
			d-cache-block-size = <64>;
			d-cache-size = <65536>;
			d-cache-sets = <512>;
			next-level-cache = <&l2_cache14>;
			mmu-type = "riscv,sv39";
			numa-node-id = <3>;

			cpu56_intc: interrupt-controller {
				#address-cells = <1>;
				compatible = "riscv,cpu-intc";
				interrupt-controller;
				#interrupt-cells = <1>;
			};
		};

		cpu57: cpu@57 {
			compatible = "thead,c920", "riscv";
			device_type = "cpu";
			riscv,isa = "rv64imafdc_xtheadvector";
			riscv,isa-base = "rv64i";
			riscv,isa-extensions = "i", "m", "a", "f", "d", "c",
					"zicntr", "zicsr", "zifencei",
					"zihpm", "xtheadvector";
			reg = <57>;
			i-cache-size = <65536>;
			i-cache-sets = <512>;
			d-cache-block-size = <64>;
			d-cache-size = <65536>;
			d-cache-sets = <512>;
			next-level-cache = <&l2_cache14>;
			mmu-type = "riscv,sv39";
			numa-node-id = <3>;

			cpu57_intc: interrupt-controller {
				#address-cells = <1>;
				compatible = "riscv,cpu-intc";
				interrupt-controller;
				#interrupt-cells = <1>;
			};
		};

		cpu58: cpu@58 {
			compatible = "thead,c920", "riscv";
			device_type = "cpu";
			riscv,isa = "rv64imafdc_xtheadvector";
			riscv,isa-base = "rv64i";
			riscv,isa-extensions = "i", "m", "a", "f", "d", "c",
					"zicntr", "zicsr", "zifencei",
					"zihpm", "xtheadvector";
			reg = <58>;
			i-cache-size = <65536>;
			i-cache-sets = <512>;
			d-cache-block-size = <64>;
			d-cache-size = <65536>;
			d-cache-sets = <512>;
			next-level-cache = <&l2_cache14>;
			mmu-type = "riscv,sv39";
			numa-node-id = <3>;

			cpu58_intc: interrupt-controller {
				#address-cells = <1>;
				compatible = "riscv,cpu-intc";
				interrupt-controller;
				#interrupt-cells = <1>;
			};
		};

		cpu59: cpu@59 {
			compatible = "thead,c920", "riscv";
			device_type = "cpu";
			riscv,isa = "rv64imafdc_xtheadvector";
			riscv,isa-base = "rv64i";
			riscv,isa-extensions = "i", "m", "a", "f", "d", "c",
					"zicntr", "zicsr", "zifencei",
					"zihpm", "xtheadvector";
			reg = <59>;
			i-cache-size = <65536>;
			i-cache-sets = <512>;
			d-cache-block-size = <64>;
			d-cache-size = <65536>;
			d-cache-sets = <512>;
			next-level-cache = <&l2_cache14>;
			mmu-type = "riscv,sv39";
			numa-node-id = <3>;

			cpu59_intc: interrupt-controller {
				#address-cells = <1>;
				compatible = "riscv,cpu-intc";
				interrupt-controller;
				#interrupt-cells = <1>;
			};
		};

		cpu60: cpu@60 {
			compatible = "thead,c920", "riscv";
			device_type = "cpu";
			riscv,isa = "rv64imafdc_xtheadvector";
			riscv,isa-base = "rv64i";
			riscv,isa-extensions = "i", "m", "a", "f", "d", "c",
					"zicntr", "zicsr", "zifencei",
					"zihpm", "xtheadvector";
			reg = <60>;
			i-cache-size = <65536>;
			i-cache-sets = <512>;
			d-cache-block-size = <64>;
			d-cache-size = <65536>;
			d-cache-sets = <512>;
			next-level-cache = <&l2_cache15>;
			mmu-type = "riscv,sv39";
			numa-node-id = <3>;

			cpu60_intc: interrupt-controller {
				#address-cells = <1>;
				compatible = "riscv,cpu-intc";
				interrupt-controller;
				#interrupt-cells = <1>;
			};
		};

		cpu61: cpu@61 {
			compatible = "thead,c920", "riscv";
			device_type = "cpu";
			riscv,isa = "rv64imafdc_xtheadvector";
			riscv,isa-base = "rv64i";
			riscv,isa-extensions = "i", "m", "a", "f", "d", "c",
					"zicntr", "zicsr", "zifencei",
					"zihpm", "xtheadvector";
			reg = <61>;
			i-cache-size = <65536>;
			i-cache-sets = <512>;
			d-cache-block-size = <64>;
			d-cache-size = <65536>;
			d-cache-sets = <512>;
			next-level-cache = <&l2_cache15>;
			mmu-type = "riscv,sv39";
			numa-node-id = <3>;

			cpu61_intc: interrupt-controller {
				#address-cells = <1>;
				compatible = "riscv,cpu-intc";
				interrupt-controller;
				#interrupt-cells = <1>;
			};
		};

		cpu62: cpu@62 {
			compatible = "thead,c920", "riscv";
			device_type = "cpu";
			riscv,isa = "rv64imafdc_xtheadvector";
			riscv,isa-base = "rv64i";
			riscv,isa-extensions = "i", "m", "a", "f", "d", "c",
					"zicntr", "zicsr", "zifencei",
					"zihpm", "xtheadvector";
			reg = <62>;
			i-cache-block-size = <64>;
			i-cache-size = <65536>;
			i-cache-sets = <512>;
			d-cache-block-size = <64>;
			d-cache-size = <65536>;
			d-cache-sets = <512>;
			next-level-cache = <&l2_cache15>;
			mmu-type = "riscv,sv39";
			numa-node-id = <3>;

			cpu62_intc: interrupt-controller {
				#address-cells = <1>;
				compatible = "riscv,cpu-intc";
				interrupt-controller;
				#interrupt-cells = <1>;
			};
		};

		cpu63: cpu@63 {
			compatible = "thead,c920", "riscv";
			device_type = "cpu";
			riscv,isa = "rv64imafdc_xtheadvector";
			riscv,isa-base = "rv64i";
			riscv,isa-extensions = "i", "m", "a", "f", "d", "c",
					"zicntr", "zicsr", "zifencei",
					"zihpm", "xtheadvector";
			reg = <63>;
			i-cache-block-size = <64>;
			i-cache-size = <65536>;
			i-cache-sets = <512>;
			d-cache-block-size = <64>;
			d-cache-size = <65536>;
			d-cache-sets = <512>;
			next-level-cache = <&l2_cache15>;
			mmu-type = "riscv,sv39";
			numa-node-id = <3>;

			cpu63_intc: interrupt-controller {
				#address-cells = <1>;
				compatible = "riscv,cpu-intc";
				interrupt-controller;
				#interrupt-cells = <1>;
			};
		};

		l2_cache0: cache-controller-0 {
			compatible = "cache";
			cache-block-size = <64>;
			cache-level = <2>;
			cache-size = <1048576>;
			cache-sets = <1024>;
			cache-unified;
			next-level-cache = <&l3_cache0>;
		};

		l2_cache1: cache-controller-1 {
			compatible = "cache";
			cache-block-size = <64>;
			cache-level = <2>;
			cache-size = <1048576>;
			cache-sets = <1024>;
			cache-unified;
			next-level-cache = <&l3_cache0>;
		};

		l2_cache2: cache-controller-2 {
			compatible = "cache";
			cache-block-size = <64>;
			cache-level = <2>;
			cache-size = <1048576>;
			cache-sets = <1024>;
			cache-unified;
			next-level-cache = <&l3_cache0>;
		};

		l2_cache3: cache-controller-3 {
			compatible = "cache";
			cache-block-size = <64>;
			cache-level = <2>;
			cache-size = <1048576>;
			cache-sets = <1024>;
			cache-unified;
			next-level-cache = <&l3_cache0>;
		};

		l2_cache4: cache-controller-4 {
			compatible = "cache";
			cache-block-size = <64>;
			cache-level = <2>;
			cache-size = <1048576>;
			cache-sets = <1024>;
			cache-unified;
			next-level-cache = <&l3_cache0>;
		};

		l2_cache5: cache-controller-5 {
			compatible = "cache";
			cache-block-size = <64>;
			cache-level = <2>;
			cache-size = <1048576>;
			cache-sets = <1024>;
			cache-unified;
			next-level-cache = <&l3_cache0>;
		};

		l2_cache6: cache-controller-6 {
			compatible = "cache";
			cache-block-size = <64>;
			cache-level = <2>;
			cache-size = <1048576>;
			cache-sets = <1024>;
			cache-unified;
			next-level-cache = <&l3_cache0>;
		};

		l2_cache7: cache-controller-7 {
			compatible = "cache";
			cache-block-size = <64>;
			cache-level = <2>;
			cache-size = <1048576>;
			cache-sets = <1024>;
			cache-unified;
			next-level-cache = <&l3_cache0>;
		};

		l2_cache8: cache-controller-8 {
			compatible = "cache";
			cache-block-size = <64>;
			cache-level = <2>;
			cache-size = <1048576>;
			cache-sets = <1024>;
			cache-unified;
			next-level-cache = <&l3_cache0>;
		};

		l2_cache9: cache-controller-9 {
			compatible = "cache";
			cache-block-size = <64>;
			cache-level = <2>;
			cache-size = <1048576>;
			cache-sets = <1024>;
			cache-unified;
			next-level-cache = <&l3_cache0>;
		};

		l2_cache10: cache-controller-10 {
			compatible = "cache";
			cache-block-size = <64>;
			cache-level = <2>;
			cache-size = <1048576>;
			cache-sets = <1024>;
			cache-unified;
			next-level-cache = <&l3_cache0>;
		};

		l2_cache11: cache-controller-11 {
			compatible = "cache";
			cache-block-size = <64>;
			cache-level = <2>;
			cache-size = <1048576>;
			cache-sets = <1024>;
			cache-unified;
			next-level-cache = <&l3_cache0>;
		};

		l2_cache12: cache-controller-12 {
			compatible = "cache";
			cache-block-size = <64>;
			cache-level = <2>;
			cache-size = <1048576>;
			cache-sets = <1024>;
			cache-unified;
			next-level-cache = <&l3_cache0>;
		};

		l2_cache13: cache-controller-13 {
			compatible = "cache";
			cache-block-size = <64>;
			cache-level = <2>;
			cache-size = <1048576>;
			cache-sets = <1024>;
			cache-unified;
			next-level-cache = <&l3_cache0>;
		};

		l2_cache14: cache-controller-14 {
			compatible = "cache";
			cache-block-size = <64>;
			cache-level = <2>;
			cache-size = <1048576>;
			cache-sets = <1024>;
			cache-unified;
			next-level-cache = <&l3_cache0>;
		};

		l2_cache15: cache-controller-15 {
			compatible = "cache";
			cache-block-size = <64>;
			cache-level = <2>;
			cache-size = <1048576>;
			cache-sets = <1024>;
			cache-unified;
			next-level-cache = <&l3_cache0>;
		};

		l3_cache0: cache-controller-130 {
			compatible = "cache";
			cache-block-size = <64>;
			cache-level = <3>;
			cache-size = <67108864>;
			cache-sets = <4096>;
			cache-unified;
		};
	};


	pmu {
		compatible = "riscv,pmu";
		riscv,event-to-mhpmevent =
			<0x00003 0x00000000 0x00000010>,
			<0x00004 0x00000000 0x00000011>,
			<0x00005 0x00000000 0x00000007>,
			<0x00006 0x00000000 0x00000006>,
			<0x00008 0x00000000 0x00000027>,
			<0x00009 0x00000000 0x00000028>,
			<0x10000 0x00000000 0x0000000c>,
			<0x10001 0x00000000 0x0000000d>,
			<0x10002 0x00000000 0x0000000e>,
			<0x10003 0x00000000 0x0000000f>,
			<0x10008 0x00000000 0x00000001>,
			<0x10009 0x00000000 0x00000002>,
			<0x10010 0x00000000 0x00000010>,
			<0x10011 0x00000000 0x00000011>,
			<0x10012 0x00000000 0x00000012>,
			<0x10013 0x00000000 0x00000013>,
			<0x10019 0x00000000 0x00000004>,
			<0x10021 0x00000000 0x00000003>,
			<0x10030 0x00000000 0x0000001c>,
			<0x10031 0x00000000 0x0000001b>;
		riscv,event-to-mhpmcounters =
			<0x00003 0x00003 0xfffffff8>,
			<0x00004 0x00004 0xfffffff8>,
			<0x00005 0x00005 0xfffffff8>,
			<0x00006 0x00006 0xfffffff8>,
			<0x00007 0x00007 0xfffffff8>,
			<0x00008 0x00008 0xfffffff8>,
			<0x00009 0x00009 0xfffffff8>,
			<0x0000a 0x0000a 0xfffffff8>,
			<0x10000 0x10000 0xfffffff8>,
			<0x10001 0x10001 0xfffffff8>,
			<0x10002 0x10002 0xfffffff8>,
			<0x10003 0x10003 0xfffffff8>,
			<0x10008 0x10008 0xfffffff8>,
			<0x10009 0x10009 0xfffffff8>,
			<0x10010 0x10010 0xfffffff8>,
			<0x10011 0x10011 0xfffffff8>,
			<0x10012 0x10012 0xfffffff8>,
			<0x10013 0x10013 0xfffffff8>,
			<0x10019 0x10019 0xfffffff8>,
			<0x10021 0x10021 0xfffffff8>,
			<0x10030 0x10030 0xfffffff8>,
			<0x10031 0x10031 0xfffffff8>;
		riscv,raw-event-to-mhpmcounters =
			<0x00000000 0x00000001 0xffffffff 0xffffffff 0xfffffff8>,
			<0x00000000 0x00000002 0xffffffff 0xffffffff 0xfffffff8>,
			<0x00000000 0x00000003 0xffffffff 0xffffffff 0xfffffff8>,
			<0x00000000 0x00000004 0xffffffff 0xffffffff 0xfffffff8>,
			<0x00000000 0x00000005 0xffffffff 0xffffffff 0xfffffff8>,
			<0x00000000 0x00000006 0xffffffff 0xffffffff 0xfffffff8>,
			<0x00000000 0x00000007 0xffffffff 0xffffffff 0xfffffff8>,
			<0x00000000 0x00000008 0xffffffff 0xffffffff 0xfffffff8>,
			<0x00000000 0x00000009 0xffffffff 0xffffffff 0xfffffff8>,
			<0x00000000 0x0000000a 0xffffffff 0xffffffff 0xfffffff8>,
			<0x00000000 0x0000000b 0xffffffff 0xffffffff 0xfffffff8>,
			<0x00000000 0x0000000c 0xffffffff 0xffffffff 0xfffffff8>,
			<0x00000000 0x0000000d 0xffffffff 0xffffffff 0xfffffff8>,
			<0x00000000 0x0000000e 0xffffffff 0xffffffff 0xfffffff8>,
			<0x00000000 0x0000000f 0xffffffff 0xffffffff 0xfffffff8>,
			<0x00000000 0x00000010 0xffffffff 0xffffffff 0xfffffff8>,
			<0x00000000 0x00000011 0xffffffff 0xffffffff 0xfffffff8>,
			<0x00000000 0x00000012 0xffffffff 0xffffffff 0xfffffff8>,
			<0x00000000 0x00000013 0xffffffff 0xffffffff 0xfffffff8>,
			<0x00000000 0x00000014 0xffffffff 0xffffffff 0xfffffff8>,
			<0x00000000 0x00000015 0xffffffff 0xffffffff 0xfffffff8>,
			<0x00000000 0x00000016 0xffffffff 0xffffffff 0xfffffff8>,
			<0x00000000 0x00000017 0xffffffff 0xffffffff 0xfffffff8>,
			<0x00000000 0x00000018 0xffffffff 0xffffffff 0xfffffff8>,
			<0x00000000 0x00000019 0xffffffff 0xffffffff 0xfffffff8>,
			<0x00000000 0x0000001a 0xffffffff 0xffffffff 0xfffffff8>,
			<0x00000000 0x0000001b 0xffffffff 0xffffffff 0xfffffff8>,
			<0x00000000 0x0000001c 0xffffffff 0xffffffff 0xfffffff8>,
			<0x00000000 0x0000001d 0xffffffff 0xffffffff 0xfffffff8>,
			<0x00000000 0x0000001e 0xffffffff 0xffffffff 0xfffffff8>,
			<0x00000000 0x0000001f 0xffffffff 0xffffffff 0xfffffff8>,
			<0x00000000 0x00000020 0xffffffff 0xffffffff 0xfffffff8>,
			<0x00000000 0x00000021 0xffffffff 0xffffffff 0xfffffff8>,
			<0x00000000 0x00000022 0xffffffff 0xffffffff 0xfffffff8>,
			<0x00000000 0x00000023 0xffffffff 0xffffffff 0xfffffff8>,
			<0x00000000 0x00000024 0xffffffff 0xffffffff 0xfffffff8>,
			<0x00000000 0x00000025 0xffffffff 0xffffffff 0xfffffff8>,
			<0x00000000 0x00000026 0xffffffff 0xffffffff 0xfffffff8>,
			<0x00000000 0x00000027 0xffffffff 0xffffffff 0xfffffff8>,
			<0x00000000 0x00000028 0xffffffff 0xffffffff 0xfffffff8>,
			<0x00000000 0x00000029 0xffffffff 0xffffffff 0xfffffff8>,
			<0x00000000 0x0000002a 0xffffffff 0xffffffff 0xfffffff8>;
	};

	soc: soc {
		#address-cells = <2>;
		#size-cells = <2>;
		compatible = "simple-bus";
		ranges;
		dma-ranges = <0x0 0x0 0x0 0x0 0x1f 0x0>;

		top_misc: top_misc_ctrl@7030010000 {
			compatible = "syscon";
			reg = <0x70 0x30010000 0x0 0x8000>;
		};

		clint_mswi: clint-mswi@7094000000 {
			compatible = "thead,c900-clint-mswi";
			reg = <0x00000070 0x94000000 0x00000000 0x00004000>;
			interrupts-extended = <
				&cpu0_intc 3
				&cpu1_intc 3
				&cpu2_intc 3
				&cpu3_intc 3
				&cpu4_intc 3
				&cpu5_intc 3
				&cpu6_intc 3
				&cpu7_intc 3
				&cpu8_intc 3
				&cpu9_intc 3
				&cpu10_intc 3
				&cpu11_intc 3
				&cpu12_intc 3
				&cpu13_intc 3
				&cpu14_intc 3
				&cpu15_intc 3
				&cpu16_intc 3
				&cpu17_intc 3
				&cpu18_intc 3
				&cpu19_intc 3
				&cpu20_intc 3
				&cpu21_intc 3
				&cpu22_intc 3
				&cpu23_intc 3
				&cpu24_intc 3
				&cpu25_intc 3
				&cpu26_intc 3
				&cpu27_intc 3
				&cpu28_intc 3
				&cpu29_intc 3
				&cpu30_intc 3
				&cpu31_intc 3
				&cpu32_intc 3
				&cpu33_intc 3
				&cpu34_intc 3
				&cpu35_intc 3
				&cpu36_intc 3
				&cpu37_intc 3
				&cpu38_intc 3
				&cpu39_intc 3
				&cpu40_intc 3
				&cpu41_intc 3
				&cpu42_intc 3
				&cpu43_intc 3
				&cpu44_intc 3
				&cpu45_intc 3
				&cpu46_intc 3
				&cpu47_intc 3
				&cpu48_intc 3
				&cpu49_intc 3
				&cpu50_intc 3
				&cpu51_intc 3
				&cpu52_intc 3
				&cpu53_intc 3
				&cpu54_intc 3
				&cpu55_intc 3
				&cpu56_intc 3
				&cpu57_intc 3
				&cpu58_intc 3
				&cpu59_intc 3
				&cpu60_intc 3
				&cpu61_intc 3
				&cpu62_intc 3
				&cpu63_intc 3
				>;
		};

		clint_mtimer0: clint-mtimer@70ac000000 {
			compatible = "thead,c900-clint-mtimer";
			reg = <0x00000070 0xac000000 0x00000000 0x00007ff8>;
			interrupts-extended = <
				&cpu0_intc 7
				&cpu1_intc 7
				&cpu2_intc 7
				&cpu3_intc 7
				>;
		};

		clint_mtimer1: clint-mtimer@70ac010000 {
			compatible = "thead,c900-clint-mtimer";
			reg = <0x00000070 0xac010000 0x00000000 0x00007ff8>;
			interrupts-extended = <
				&cpu4_intc 7
				&cpu5_intc 7
				&cpu6_intc 7
				&cpu7_intc 7
				>;
		};

		clint_mtimer2: clint-mtimer@70ac020000 {
			compatible = "thead,c900-clint-mtimer";
			reg = <0x00000070 0xac020000 0x00000000 0x00007ff8>;
			interrupts-extended = <
				&cpu8_intc 7
				&cpu9_intc 7
				&cpu10_intc 7
				&cpu11_intc 7
				>;
		};

		clint_mtimer3: clint-mtimer@70ac030000 {
			compatible = "thead,c900-clint-mtimer";
			reg = <0x00000070 0xac030000 0x00000000 0x00007ff8>;
			interrupts-extended = <
				&cpu12_intc 7
				&cpu13_intc 7
				&cpu14_intc 7
				&cpu15_intc 7
				>;
		};

		clint_mtimer4: clint-mtimer@70ac040000 {
			compatible = "thead,c900-clint-mtimer";
			reg = <0x00000070 0xac040000 0x00000000 0x00007ff8>;
			interrupts-extended = <
				&cpu16_intc 7
				&cpu17_intc 7
				&cpu18_intc 7
				&cpu19_intc 7
				>;
		};

		clint_mtimer5: clint-mtimer@70ac050000 {
			compatible = "thead,c900-clint-mtimer";
			reg = <0x00000070 0xac050000 0x00000000 0x00007ff8>;
			interrupts-extended = <
				&cpu20_intc 7
				&cpu21_intc 7
				&cpu22_intc 7
				&cpu23_intc 7
				>;
		};

		clint_mtimer6: clint-mtimer@70ac060000 {
			compatible = "thead,c900-clint-mtimer";
			reg = <0x00000070 0xac060000 0x00000000 0x00007ff8>;
			interrupts-extended = <
				&cpu24_intc 7
				&cpu25_intc 7
				&cpu26_intc 7
				&cpu27_intc 7
				>;
		};

		clint_mtimer7: clint-mtimer@70ac070000 {
			compatible = "thead,c900-clint-mtimer";
			reg = <0x00000070 0xac070000 0x00000000 0x00007ff8>;
			interrupts-extended = <
				&cpu28_intc 7
				&cpu29_intc 7
				&cpu30_intc 7
				&cpu31_intc 7
				>;
		};

		clint_mtimer8: clint-mtimer@70ac080000 {
			compatible = "thead,c900-clint-mtimer";
			reg = <0x00000070 0xac080000 0x00000000 0x00007ff8>;
			interrupts-extended = <
				&cpu32_intc 7
				&cpu33_intc 7
				&cpu34_intc 7
				&cpu35_intc 7
				>;
		};

		clint_mtimer9: clint-mtimer@70ac090000 {
			compatible = "thead,c900-clint-mtimer";
			reg = <0x00000070 0xac090000 0x00000000 0x00007ff8>;
			interrupts-extended = <
				&cpu36_intc 7
				&cpu37_intc 7
				&cpu38_intc 7
				&cpu39_intc 7
				>;
		};

		clint_mtimer10: clint-mtimer@70ac0a0000 {
			compatible = "thead,c900-clint-mtimer";
			reg = <0x00000070 0xac0a0000 0x00000000 0x00007ff8>;
			interrupts-extended = <
				&cpu40_intc 7
				&cpu41_intc 7
				&cpu42_intc 7
				&cpu43_intc 7
				>;
		};

		clint_mtimer11: clint-mtimer@70ac0b0000 {
			compatible = "thead,c900-clint-mtimer";
			reg = <0x00000070 0xac0b0000 0x00000000 0x00007ff8>;
			interrupts-extended = <
				&cpu44_intc 7
				&cpu45_intc 7
				&cpu46_intc 7
				&cpu47_intc 7
				>;
		};

		clint_mtimer12: clint-mtimer@70ac0c0000 {
			compatible = "thead,c900-clint-mtimer";
			reg = <0x00000070 0xac0c0000 0x00000000 0x00007ff8>;
			interrupts-extended = <
				&cpu48_intc 7
				&cpu49_intc 7
				&cpu50_intc 7
				&cpu51_intc 7
				>;
		};

		clint_mtimer13: clint-mtimer@70ac0d0000 {
			compatible = "thead,c900-clint-mtimer";
			reg = <0x00000070 0xac0d0000 0x00000000 0x00007ff8>;
			interrupts-extended = <
				&cpu52_intc 7
				&cpu53_intc 7
				&cpu54_intc 7
				&cpu55_intc 7
				>;
		};

		clint_mtimer14: clint-mtimer@70ac0e0000 {
			compatible = "thead,c900-clint-mtimer";
			reg = <0x00000070 0xac0e0000 0x00000000 0x00007ff8>;
			interrupts-extended = <
				&cpu56_intc 7
				&cpu57_intc 7
				&cpu58_intc 7
				&cpu59_intc 7
				>;
		};

		clint_mtimer15: clint-mtimer@70ac0f0000 {
			compatible = "thead,c900-clint-mtimer";
			reg = <0x00000070 0xac0f0000 0x00000000 0x00007ff8>;
			interrupts-extended = <
				&cpu60_intc 7
				&cpu61_intc 7
				&cpu62_intc 7
				&cpu63_intc 7
				>;
		};

		intc: interrupt-controller@7090000000 {
			#address-cells = <0>;
			#interrupt-cells = <2>;
			compatible = "thead,c900-plic";
			interrupt-controller;
			interrupts-extended = <
				&cpu0_intc  11 &cpu0_intc  9
				&cpu1_intc  11 &cpu1_intc  9
				&cpu2_intc  11 &cpu2_intc  9
				&cpu3_intc  11 &cpu3_intc  9
				&cpu4_intc  11 &cpu4_intc  9
				&cpu5_intc  11 &cpu5_intc  9
				&cpu6_intc  11 &cpu6_intc  9
				&cpu7_intc  11 &cpu7_intc  9
				&cpu8_intc  11 &cpu8_intc  9
				&cpu9_intc  11 &cpu9_intc  9
				&cpu10_intc  11 &cpu10_intc  9
				&cpu11_intc  11 &cpu11_intc  9
				&cpu12_intc  11 &cpu12_intc  9
				&cpu13_intc  11 &cpu13_intc  9
				&cpu14_intc  11 &cpu14_intc  9
				&cpu15_intc  11 &cpu15_intc  9
				&cpu16_intc  11 &cpu16_intc  9
				&cpu17_intc  11 &cpu17_intc  9
				&cpu18_intc  11 &cpu18_intc  9
				&cpu19_intc  11 &cpu19_intc  9
				&cpu20_intc  11 &cpu20_intc  9
				&cpu21_intc  11 &cpu21_intc  9
				&cpu22_intc  11 &cpu22_intc  9
				&cpu23_intc  11 &cpu23_intc  9
				&cpu24_intc  11 &cpu24_intc  9
				&cpu25_intc  11 &cpu25_intc  9
				&cpu26_intc  11 &cpu26_intc  9
				&cpu27_intc  11 &cpu27_intc  9
				&cpu28_intc  11 &cpu28_intc  9
				&cpu29_intc  11 &cpu29_intc  9
				&cpu30_intc  11 &cpu30_intc  9
				&cpu31_intc  11 &cpu31_intc  9
				&cpu32_intc  11 &cpu32_intc  9
				&cpu33_intc  11 &cpu33_intc  9
				&cpu34_intc  11 &cpu34_intc  9
				&cpu35_intc  11 &cpu35_intc  9
				&cpu36_intc  11 &cpu36_intc  9
				&cpu37_intc  11 &cpu37_intc  9
				&cpu38_intc  11 &cpu38_intc  9
				&cpu39_intc  11 &cpu39_intc  9
				&cpu40_intc  11 &cpu40_intc  9
				&cpu41_intc  11 &cpu41_intc  9
				&cpu42_intc  11 &cpu42_intc  9
				&cpu43_intc  11 &cpu43_intc  9
				&cpu44_intc  11 &cpu44_intc  9
				&cpu45_intc  11 &cpu45_intc  9
				&cpu46_intc  11 &cpu46_intc  9
				&cpu47_intc  11 &cpu47_intc  9
				&cpu48_intc  11 &cpu48_intc  9
				&cpu49_intc  11 &cpu49_intc  9
				&cpu50_intc  11 &cpu50_intc  9
				&cpu51_intc  11 &cpu51_intc  9
				&cpu52_intc  11 &cpu52_intc  9
				&cpu53_intc  11 &cpu53_intc  9
				&cpu54_intc  11 &cpu54_intc  9
				&cpu55_intc  11 &cpu55_intc  9
				&cpu56_intc  11 &cpu56_intc  9
				&cpu57_intc  11 &cpu57_intc  9
				&cpu58_intc  11 &cpu58_intc  9
				&cpu59_intc  11 &cpu59_intc  9
				&cpu60_intc  11 &cpu60_intc  9
				&cpu61_intc  11 &cpu61_intc  9
				&cpu62_intc  11 &cpu62_intc  9
				&cpu63_intc  11 &cpu63_intc  9
				>;
			reg = <0x00000070 0x90000000 0x00000000 0x04000000>;
			reg-names = "control";
			riscv,max-priority = <7>;
			riscv,ndev = <224>;
		};

		i2c0: i2c@7030005000 {
			#address-cells = <1>;
			#size-cells = <0>;
			compatible = "snps,designware-i2c";
			reg = <0x70 0x30005000 0x0 0x1000>;
			clock-frequency = <100000>;
			alias = "i2c0";
		};

		i2c1: i2c@7030006000 {
			#address-cells = <1>;
			#size-cells = <0>;
			compatible = "snps,designware-i2c";
			reg = <0x70 0x30006000 0x0 0x1000>;
			clock-frequency = <100000>;
			alias = "i2c1";

			mango_srst: mango-reset@17 {
				compatible = "mango,reset";
				reg = <0x17>;
			};
		};

		i2c2: i2c@7030007000 {
			#address-cells = <1>;
			#size-cells = <0>;
			compatible = "snps,designware-i2c";
			reg = <0x70 0x30007000 0x0 0x1000>;
			clock-frequency = <100000>;
			alias = "i2c2";
		};

		i2c3: i2c@7030008000 {
			#address-cells = <1>;
			#size-cells = <0>;
			compatible = "snps,designware-i2c";
			reg = <0x70 0x30008000 0x0 0x1000>;
			clock-frequency = <100000>;
			alias = "i2c3";
		};

		gpio0: gpio@7030009000 {
			compatible = "snps,dw-apb-gpio";
			reg = <0x70 0x30009000 0x0 0x400>;
			#address-cells = <1>;
			#size-cells = <0>;
			alias = "gpio0";

			port0a: gpio-controller@0 {
				compatible = "snps,dw-apb-gpio-port";
				bank-name = "port0a";
				gpio-controller;
				#gpio-cells = <2>;
				snps,nr-gpios = <32>;
				reg = <0>;
			};
		};

		gpio1: gpio@703000a000 {
			compatible = "snps,dw-apb-gpio";
			reg = <0x70 0x3000a000 0x0 0x400>;
			#address-cells = <1>;
			#size-cells = <0>;
			alias = "gpio1";

			port1a: gpio-controller@0 {
				compatible = "snps,dw-apb-gpio-port";
				bank-name = "port0a";
				gpio-controller;
				#gpio-cells = <2>;
				snps,nr-gpios = <32>;
				reg = <0>;
			};
		};

		gpio2: gpio@703000b000 {
			compatible = "snps,dw-apb-gpio";
			reg = <0x70 0x3000b000 0x0 0x400>;
			#address-cells = <1>;
			#size-cells = <0>;
			alias = "gpio2";

			port2a: gpio-controller@0 {
				compatible = "snps,dw-apb-gpio-port";
				bank-name = "port0a";
				gpio-controller;
				#gpio-cells = <2>;
				snps,nr-gpios = <32>;
				reg = <0>;
			};
		};

		serial@7040000000 {
			compatible = "snps,dw-apb-uart";
			reg = <0x00000070 0x40000000 0x00000000 0x00001000>;
			clock-frequency = <500000000>;
			current-speed = <115200>;
			reg-shift = <2>;
			reg-io-width = <4>;
			stdio;
		};

		sd: bm-sd@704002b000 {
			compatible = "bitmain,bm-sd", "sophgo,sg2044-dwcmshc";
			reg = <0x70 0x4002B000 0x0 0x1000>;
			bus-width = <4>;
			alias = "sd0";
		};

		spifmc0: flash-controller@7000180000 {
			compatible = "sophgo,spifmc";
			reg = <0x70 0x00180000 0x0 0x1000000>;
			reg-names = "memory";
			#address-cells = <1>;
			#size-cells = <0>;
			clock-frequency = <100000000>;
			sophgo-config;
			alias = "flash0";
			flash@0 {
				reg = <0>;
				compatible = "jedec,spi-nor";
			};
		};

		spifmc1: flash-controller@7002180000 {
			compatible = "sophgo,spifmc";
			reg = <0x70 0x02180000 0x0 0x1000000>;
			reg-names = "memory";
			#address-cells = <1>;
			#size-cells = <0>;
			clock-frequency = <100000000>;
			sophgo-boot = <0x00000000 0x00600000>;
			alias = "flash1";
			flash@0 {
				reg = <0>;
				compatible = "jedec,spi-nor";
			};
		};

		pcie0: pcie@7060000000 {
			compatible = "sophgo,cdns-pcie-host";
			device_type = "pci";
			#address-cells = <3>;
			#size-cells = <2>;

			bus-range = <0x0 0x3f>;
			linux,pci-domain = <0>;
			cdns,max-outbound-regions = <16>;
			cdns,no-bar-match-nbits = <48>;
			vendor-id = /bits/ 16 <0x1E30>;
			device-id = /bits/ 16 <0x2042>;
			pcie-id = /bits/ 16 <0x0>;
			link-id = /bits/ 16 <0x0>;
			reg = <0x70 0x60000000  0x0 0x02000000>,
			<0x40 0x00000000  0x0 0x00001000>;
			reg-names = "reg", "cfg";

			// IO, check IO_SPACE_LIMIT
			// 32bit prefetchable memory
			// 32bit non-prefetchable memory
			// 64bit prefetchable memory
			// 64bit non-prefetchable memory
			ranges = <0x01000000 0x0  0xc0000000  0x40 0xc0000000  0x0 0x00400000>,
				<0x42000000 0x0  0xd0000000  0x40 0xd0000000  0x0 0x10000000>,
				<0x02000000 0x0  0xe0000000  0x40 0xe0000000  0x0 0x20000000>,
				<0x43000000 0x42 0x00000000  0x42 0x00000000  0x2 0x00000000>,
				<0x03000000 0x41 0x00000000  0x41 0x00000000  0x1 0x00000000>;

			status = "okay";
		};

		pcie1: pcie@7060800000 {
			compatible = "sophgo,cdns-pcie-host";
			device_type = "pci";
			#address-cells = <3>;
			#size-cells = <2>;

			bus-range = <0x40 0x7f>;
			linux,pci-domain = <1>;
			cdns,max-outbound-regions = <16>;
			cdns,no-bar-match-nbits = <48>;
			vendor-id = /bits/ 16 <0x1E30>;
			device-id = /bits/ 16 <0x2042>;
			pcie-id = /bits/ 16 <0x0>;
			link-id = /bits/ 16 <0x1>;
			reg = <0x44 0x00000000  0x0 0x00001000>;
			reg-names = "cfg";

			// IO, check IO_SPACE_LIMIT
			// 32bit prefetchable memory
			// 32bit non-prefetchable memory
			// 64bit prefetchable memory
			// 64bit non-prefetchable memory
			ranges = <0x01000000 0x0  0xc0400000  0x44 0xc0400000  0x0 0x00400000>,
				<0x42000000 0x0  0xe0000000  0x44 0xe0000000  0x0 0x20000000>,
				<0x02000000 0x0  0xd0000000  0x44 0xd0000000  0x0 0x10000000>,
				<0x43000000 0x46 0x00000000  0x46 0x00000000  0x2 0x00000000>,
				<0x03000000 0x45 0x00000000  0x45 0x00000000  0x1 0x00000000>;

			status = "okay";
		};

		pcie2: pcie@7062000000 {
			compatible = "sophgo,cdns-pcie-host";
			device_type = "pci";
			#address-cells = <3>;
			#size-cells = <2>;

			bus-range = <0x80 0xff>;
			linux,pci-domain = <2>;
			cdns,max-outbound-regions = <16>;
			cdns,no-bar-match-nbits = <48>;
			vendor-id = /bits/ 16 <0x1E30>;
			device-id = /bits/ 16 <0x2042>;
			pcie-id = /bits/ 16 <0x1>;
			link-id = /bits/ 16 <0x0>;
			reg = <0x70 0x62000000  0x0 0x02000000>,
			<0x48 0x00000000  0x0 0x00001000>;
			reg-names = "reg", "cfg";

			// IO, check IO_SPACE_LIMIT
			// 32bit prefetchable memory
			// 32bit non-prefetchable memory
			// 64bit prefetchable memory
			// 64bit non-prefetchable memory
			ranges = <0x01000000 0x0  0xc0800000  0x48 0xc0800000  0x0 0x00800000>,
				<0x42000000 0x0  0xd0000000  0x48 0xd0000000  0x0 0x10000000>,
				<0x02000000 0x0  0xe0000000  0x48 0xe0000000  0x0 0x20000000>,
				<0x43000000 0x4a 0x00000000  0x4a 0x00000000  0x2 0x00000000>,
				<0x03000000 0x49 0x00000000  0x49 0x00000000  0x1 0x00000000>;

			status = "okay";
		};
	};
};
